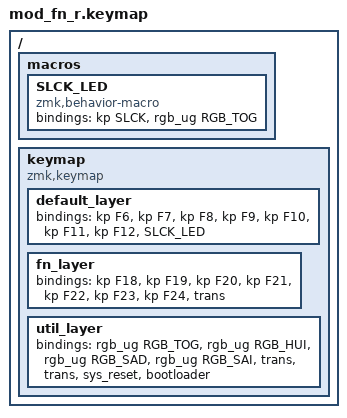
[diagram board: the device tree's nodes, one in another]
/*
 * copyright (c) 2025 ZMK project contributors
 *
 * SPDX-license-identifier: MIT
 */

#include <behaviors.dtsi>
#include <dt-bindings/zmk/keys.h>
#include <dt-bindings/zmk/rgb.h>

/ {
    macros {
        /* work-around for SCROLL LOCK LED indicator functionality */
        SLCK_LED: SLCK_LED {
            compatible = "zmk,behavior-macro";
            #binding-cells = <0>;
            bindings =
                <&kp SLCK>,
                <&rgb_ug RGB_TOG>;
        };
    };

    keymap {
        compatible = "zmk,keymap";

        default_layer {
            bindings = <
                &kp F6  &kp F7  &kp F8  &kp F9  &kp F10 &kp F11 &kp F12 &SLCK_LED
            >;
        };

        fn_layer {
            bindings = <
                &kp F18         &kp F19         &kp F20         &kp F21         &kp F22 &kp F23 &kp F24     &trans
            >;
        };
        
        util_layer{
            bindings = <
                &rgb_ug RGB_TOG &rgb_ug RGB_HUI &rgb_ug RGB_SAD &rgb_ug RGB_SAI &trans  &trans  &sys_reset  &bootloader
            >;
        };
    };
};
